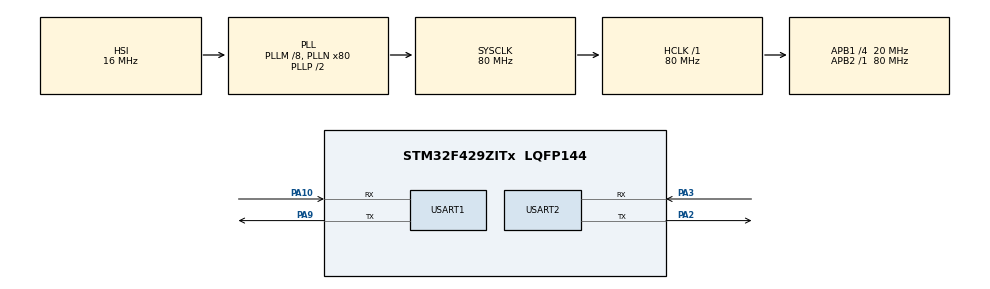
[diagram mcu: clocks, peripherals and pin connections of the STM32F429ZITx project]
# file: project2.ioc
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Mcu.Family=STM32F4
Mcu.Name=STM32F429ZITx
Mcu.Package=LQFP144
NVIC.PriorityGroup=NVIC_PRIORITYGROUP_4
NVIC.USART1_IRQn=true\:0\:0\:false\:false\:true\:true\:true\:true
NVIC.USART2_IRQn=true\:0\:0\:false\:false\:true\:true\:true\:true
PA10.Mode=Asynchronous
PA10.Signal=USART1_RX
PA13.Mode=Serial_Wire
PA13.Signal=SYS_JTMS-SWDIO
PA14.Mode=Serial_Wire
PA14.Signal=SYS_JTCK-SWCLK
PA2.Mode=Asynchronous
PA2.Signal=USART2_TX
PA3.Mode=Asynchronous
PA3.Signal=USART2_RX
PA9.GPIO_ModeDefaultPP=GPIO_MODE_AF_PP
PA9.GPIO_PuPd=GPIO_NOPULL
PA9.GPIO_Speed=GPIO_SPEED_FREQ_VERY_HIGH
PA9.Mode=Asynchronous
PA9.Signal=USART1_TX
PH0/OSC_IN.Mode=HSE-External-Oscillator
PH0/OSC_IN.Signal=RCC_OSC_IN
PH1/OSC_OUT.Mode=HSE-External-Oscillator
PH1/OSC_OUT.Signal=RCC_OSC_OUT
ProjectManager.HeapSize=0x200
ProjectManager.StackSize=0x400
ProjectManager.TargetToolchain=STM32CubeIDE
RCC.48MHZClocksFreq_Value=53333333.333333336
RCC.AHBFreq_Value=80000000
RCC.APB1CLKDivider=RCC_HCLK_DIV4
RCC.APB1Freq_Value=20000000
RCC.APB1TimFreq_Value=40000000
RCC.APB2Freq_Value=80000000
RCC.APB2TimFreq_Value=80000000
RCC.CortexFreq_Value=80000000
RCC.HCLKFreq_Value=80000000
RCC.HSE_VALUE=8000000
RCC.HSI_VALUE=16000000
RCC.LSE_VALUE=32768
RCC.PLLM=8
RCC.PLLN=80
RCC.PLLQ=3
RCC.SYSCLKFreq_VALUE=80000000
RCC.SYSCLKSource=RCC_SYSCLKSOURCE_PLLCLK
RCC.VCOOutputFreq_Value=160000000
USART1.VirtualMode=VM_ASYNC
USART2.VirtualMode=VM_ASYNC
VP_RTC_VS_RTC_Activate.Mode=RTC_Enabled
board=custom

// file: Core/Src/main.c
/* USER CODE BEGIN Header */
/**
  ******************************************************************************
  * @file           : main.c
  * @brief          : Main program body
  ******************************************************************************
  * @attention
  *
  * Copyright (c) 2024 STMicroelectronics.
  * All rights reserved.
  *
  * This software is licensed under terms that can be found in the LICENSE file
  * in the root directory of this software component.
  * If no LICENSE file comes with this software, it is provided AS-IS.
  *
  ******************************************************************************
  */
/* USER CODE END Header */
#include "main.h"
#include "string.h"

 RTC_HandleTypeDef hrtc;

UART_HandleTypeDef huart1;
UART_HandleTypeDef huart2;

void SystemClock_Config(void);
static void MX_GPIO_Init(void);
static void MX_RTC_Init(void);
static void MX_USART2_UART_Init(void);
static void MX_USART1_UART_Init(void);

/* USER CODE BEGIN 0 */

char data = 0;
int bata = 0;

int buff[16] = {0,};
int bucc[16] = {0,};

//void HAL_UART_RxCpltCallback(UART_HandleTypeDef *huart)
//{
//////	loopback on USART1_RX - PA10
////	bata = huart->Instance->SR;
////	data = huart->Instance->DR;
////	huart->Instance->DR = data;
////	HAL_UART_Receive_IT(&huart1, (uint8_t*)buff, 1);
//
//	if (huart->Instance == USART1)
//	{
////		bata = huart->Instance->SR;
////		data = (char) huart->Instance->DR;
////		huart->Instance->DR = data;
////		buff[0]++;
//		HAL_UART_Transmit_IT(&huart1, (uint8_t*)buff, 1);
////		huart->Instance->SR;
////		data = huart->Instance->DR;
//////		for (int i = 0; i < 128; i++)
//////		{
//////			huart->Instance->DR = buff[i];
//////		}
//////		huart2.Instance->DR = data;
////		HAL_UART_Transmit_IT(&huart2, (uint8_t*)data, 1);
//	}
//
//	if (huart->Instance == USART2)
//	{
//		bucc[0]++;
//		HAL_UART_Transmit_IT(&huart1, (uint8_t*)bucc, 1);

//		huart->Instance->SR;
//		data = huart->Instance->DR;
//		huart1.Instance->DR = data;
//		HAL_UART_Receive_IT(&huart2, (uint8_t*)bucc, 1);
//	}
//}

void HAL_UART_TxCpltCallback(UART_HandleTypeDef *huart)
{
//	if (huart->Instance == USART2) {
//		HAL_UART_Receive_IT(&huart2, (uint8_t*)bucc, 1);
//	}
}

/* USER CODE END 0 */

int main(void)
{

  /* MCU Configuration--------------------------------------------------------*/

  /* Reset of all peripherals, Initializes the Flash interface and the Systick. */
  HAL_Init();

  /* Configure the system clock */
  SystemClock_Config();

  /* Initialize all configured peripherals */
  MX_GPIO_Init();
  MX_RTC_Init();
  MX_USART1_UART_Init();
  MX_USART2_UART_Init();
  /* USER CODE BEGIN 2 */

//  huart2.Instance;

//  HAL_UART_Transmit_IT(&huart2, (uint8_t*)bucc, 1);

//  huart1.Instance->CR1 = huart1.Instance->CR1 || (1 << 2);
  /* USER CODE END 2 */

  /* Infinite loop */
  /* USER CODE BEGIN WHILE */

//  HAL_UART_Transmit_IT(&huart1, (uint8_t*)bucc, 1);

//  __HAL_UART_ENABLE_IT(&huart1, UART_IT_RXNE);
//  __HAL_UART_ENABLE_IT(&huart2, UART_IT_RXNE);
//  HAL_UART_Receive_IT(&huart1, (uint8_t*)buff, 1);
  uint8_t txData[] = "Hello, USART2!";
  uint8_t rxData[20];
  HAL_UART_Receive_IT(&huart2, rxData, sizeof(txData));
  HAL_UART_Transmit_IT(&huart2, txData, sizeof(txData));

  HAL_UART_Transmit_IT(&huart1, rxData, sizeof(txData));
  // Пример приёма сообщения

//  HAL_UART_Receive_IT(&huart2, rxData, sizeof(txData)-1);

  while (1)
  {
//	  if (HAL_UART_Receive_IT(&huart2, rxData, sizeof(txData)-1) == HAL_OK)
//	           {
//	              int a;
//	           }
//
//	  if (USART1->SR & USART_SR_RXNE) {
//
//		    HAL_UART_Transmit_IT(&huart2, (uint8_t*)buff, 1);
//			USART1->DR = USART1->DR;
//
//
//	  }
//	  if (bucc[0]) {
//		  HAL_UART_Transmit_IT(&huart1, (uint8_t*)bucc, 1);
//		  HAL_UART_Receive_IT(&huart1, (uint8_t*)buff, 1);
//	  }
	  HAL_Delay(1000);
    /* USER CODE END WHILE */

  }
}

void SystemClock_Config(void)
{
  RCC_OscInitTypeDef RCC_OscInitStruct = {0};
  RCC_ClkInitTypeDef RCC_ClkInitStruct = {0};

  /** Configure the main internal regulator output voltage
  */
  __HAL_RCC_PWR_CLK_ENABLE();
  __HAL_PWR_VOLTAGESCALING_CONFIG(PWR_REGULATOR_VOLTAGE_SCALE3);

  /** Initializes the RCC Oscillators according to the specified parameters
  * in the RCC_OscInitTypeDef structure.
  */
  RCC_OscInitStruct.OscillatorType = RCC_OSCILLATORTYPE_HSI|RCC_OSCILLATORTYPE_LSI;
  RCC_OscInitStruct.HSIState = RCC_HSI_ON;
  RCC_OscInitStruct.HSICalibrationValue = RCC_HSICALIBRATION_DEFAULT;
  RCC_OscInitStruct.LSIState = RCC_LSI_ON;
  RCC_OscInitStruct.PLL.PLLState = RCC_PLL_ON;
  RCC_OscInitStruct.PLL.PLLSource = RCC_PLLSOURCE_HSI;
  RCC_OscInitStruct.PLL.PLLM = 8;
  RCC_OscInitStruct.PLL.PLLN = 80;
  RCC_OscInitStruct.PLL.PLLP = RCC_PLLP_DIV2;
  RCC_OscInitStruct.PLL.PLLQ = 3;
  if (HAL_RCC_OscConfig(&RCC_OscInitStruct) != HAL_OK)
  {
    Error_Handler();
  }

  /** Initializes the CPU, AHB and APB buses clocks
  */
  RCC_ClkInitStruct.ClockType = RCC_CLOCKTYPE_HCLK|RCC_CLOCKTYPE_SYSCLK
                              |RCC_CLOCKTYPE_PCLK1|RCC_CLOCKTYPE_PCLK2;
  RCC_ClkInitStruct.SYSCLKSource = RCC_SYSCLKSOURCE_PLLCLK;
  RCC_ClkInitStruct.AHBCLKDivider = RCC_SYSCLK_DIV1;
  RCC_ClkInitStruct.APB1CLKDivider = RCC_HCLK_DIV4;
  RCC_ClkInitStruct.APB2CLKDivider = RCC_HCLK_DIV1;

  if (HAL_RCC_ClockConfig(&RCC_ClkInitStruct, FLASH_LATENCY_2) != HAL_OK)
  {
    Error_Handler();
  }
}

static void MX_RTC_Init(void)
{

  /** Initialize RTC Only
  */
  hrtc.Instance = RTC;
  hrtc.Init.HourFormat = RTC_HOURFORMAT_24;
  hrtc.Init.AsynchPrediv = 127;
  hrtc.Init.SynchPrediv = 255;
  hrtc.Init.OutPut = RTC_OUTPUT_DISABLE;
  hrtc.Init.OutPutPolarity = RTC_OUTPUT_POLARITY_HIGH;
  hrtc.Init.OutPutType = RTC_OUTPUT_TYPE_OPENDRAIN;
  if (HAL_RTC_Init(&hrtc) != HAL_OK)
  {
    Error_Handler();
  }

}

static void MX_USART1_UART_Init(void)
{

  huart1.Instance = USART1;
  huart1.Init.BaudRate = 115200;
  huart1.Init.WordLength = UART_WORDLENGTH_8B;
  huart1.Init.StopBits = UART_STOPBITS_1;
  huart1.Init.Parity = UART_PARITY_NONE;
  huart1.Init.Mode = UART_MODE_TX_RX;
  huart1.Init.HwFlowCtl = UART_HWCONTROL_NONE;
  huart1.Init.OverSampling = UART_OVERSAMPLING_16;
  if (HAL_UART_Init(&huart1) != HAL_OK)
  {
    Error_Handler();
  }

}

static void MX_USART2_UART_Init(void)
{

  huart2.Instance = USART2;
  huart2.Init.BaudRate = 115200;
  huart2.Init.WordLength = UART_WORDLENGTH_8B;
  huart2.Init.StopBits = UART_STOPBITS_1;
  huart2.Init.Parity = UART_PARITY_NONE;
  huart2.Init.Mode = UART_MODE_TX_RX;
  huart2.Init.HwFlowCtl = UART_HWCONTROL_NONE;
  huart2.Init.OverSampling = UART_OVERSAMPLING_16;
  if (HAL_UART_Init(&huart2) != HAL_OK)
  {
    Error_Handler();
  }

}

static void MX_GPIO_Init(void)
{
  /* GPIO Ports Clock Enable */
  __HAL_RCC_GPIOH_CLK_ENABLE();
  __HAL_RCC_GPIOA_CLK_ENABLE();

}

void Error_Handler(void)
{
  __disable_irq();
  while (1)
  {
  }
}
